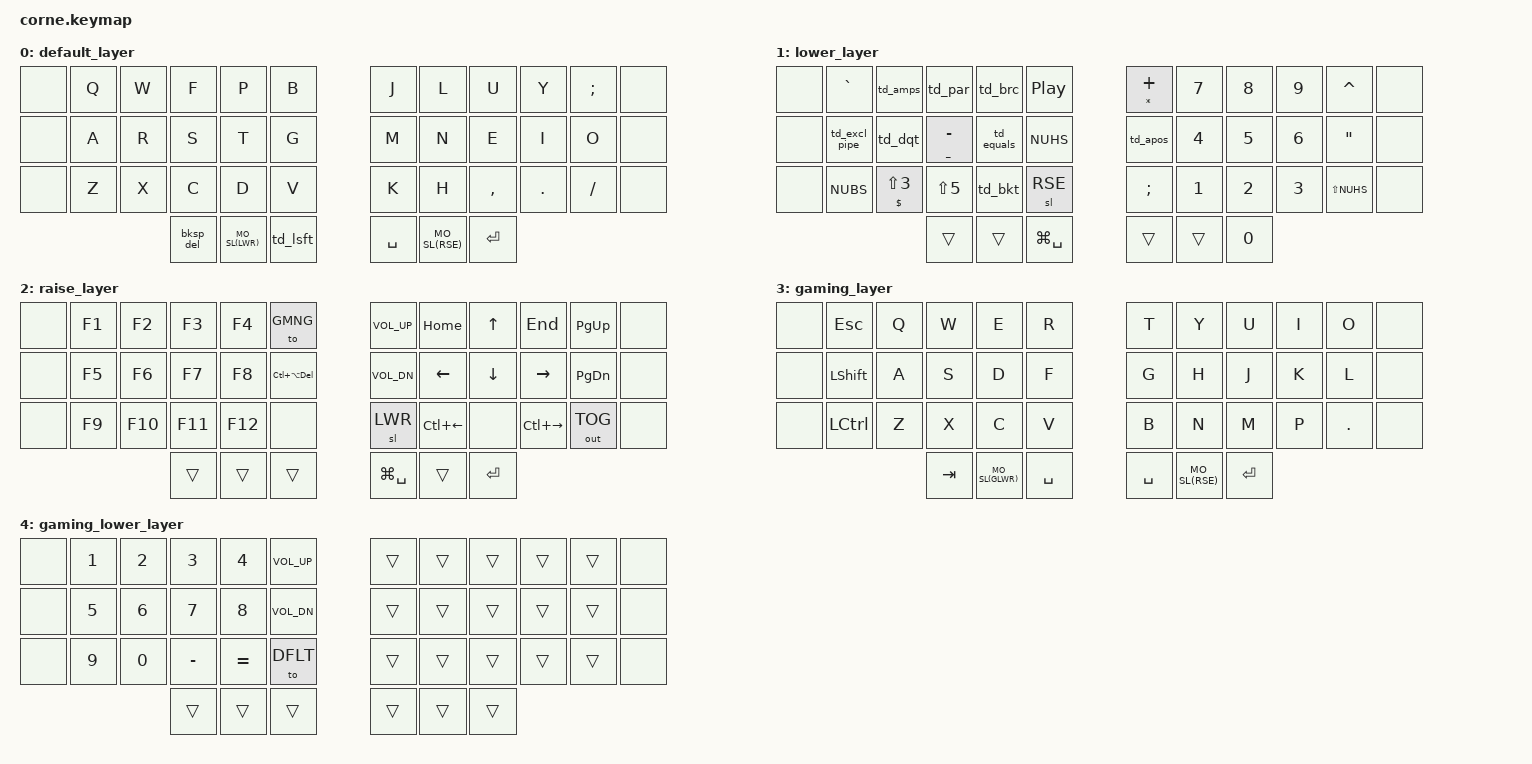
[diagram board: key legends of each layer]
/*
 * Copyright (c) 2020 The ZMK Contributors
 *
 * SPDX-License-Identifier: MIT
 */
 
/*__________________________          __________________________
XX| 1  | 2  | 3  | 4  | 5  |          | 6  | 7  | 8  | 9  | 10 |XX
XX| 13 | 14 | 15 | 16 | 17 |          | 18 | 19 | 20 | 21 | 22 |XX
XX| 25 | 26 | 27 | 28 | 29 |          | 30 | 31 | 32 | 33 | 34 |XX
                 | 36 | 37 | 38 || 39 | 40 | 41 | */

#include <behaviors.dtsi>
#include <dt-bindings/zmk/keys.h>
#include <dt-bindings/zmk/bt.h>
#include <dt-bindings/zmk/outputs.h>

#define MO_TOG(layer) &mo_tog layer layer // macro to apply momentary on hold, toggle on tap
#define MO_SL(layer) &mo_sl layer layer // macro to apply momentary on hold sticky on tap

#define DFLT 0
#define LWR 1
#define RSE 2
#define GMNG 3
#define GLWR 4

#define TD_TAPTERM 175
#define LAYER_TAPTERM 175
#define COMBO_TIMEOUT 35
#define COMBO_TIMEOUT_FAST 30

#define QUICKTAP_MS 125
#define QUICKTAP_TERM 175

#define XX &none
#define TRNS &trans

/ {
        // conditional_layers {
        //         compatible = "zmk,conditional-layers";
        //         tri_layer {
        //                 if-layers = <LWR RSE>;
        //                 then-layer = <MISC>;
        //         };
        // };
        
        macros {
                parens: parens {
                        label = "parens";
                        compatible = "zmk,behavior-macro";
                        #binding-cells = <0>;
                        bindings = <&macro_tap &kp LPAR &kp RPAR>;
                };
                braces: braces {
                        label = "braces";
                        compatible = "zmk,behavior-macro";
                        #binding-cells = <0>;
                        bindings = <&macro_tap &kp LBRC &kp RBRC>;
                };
                brackets: brackets {
                        label = "brackets";
                        compatible = "zmk,behavior-macro";
                        #binding-cells = <0>;
                        bindings = <&macro_tap &kp LBKT &kp RBKT>;
                };
                prog_brackets: prog_brackets {
                        label = "prog_brackets";
                        compatible = "zmk,behavior-macro";
                        #binding-cells = <0>;
                        bindings = <&macro_tap &kp LBKT &kp RBKT>;
                };
                quotations: quotations {
                        label = "quotations";
                        compatible = "zmk,behavior-macro";
                        #binding-cells = <0>;
                        bindings = <&macro_tap &kp AT &kp AT &kp LEFT>;
                };
                apostrophes: apostrophes {
                        label = "apostrophes";
                        compatible = "zmk,behavior-macro";
                        #binding-cells = <0>;
                        bindings = <&macro_tap &kp APOS &kp APOS &kp LEFT>;
                };
                or: or {
                        label = "or";
                        compatible = "zmk,behavior-macro";
                        #binding-cells = <0>;
                        bindings = <&macro_tap &kp LS(NUBS) &kp LS(NUBS)>;
                };
                and: and {
                        label = "and";
                        compatible = "zmk,behavior-macro";
                        #binding-cells = <0>;
                        bindings = <&macro_tap &kp LS(N7) &kp LS(N7)>;
                };
                equals: equals {
                        label = "equals";
                        compatible = "zmk,behavior-macro";
                        #binding-cells = <0>;
                        bindings = <&macro_tap &kp EQUAL &kp EQUAL>;
                };
        };

        behaviors {
                mo_tog: behavior_mo_tog {
                        compatible = "zmk,behavior-hold-tap";
                        label = "mo_tog";
                        #binding-cells = <2>;
                        flavor = "balanced";
                        tapping-term-ms = <LAYER_TAPTERM>;
                        bindings = <&mo>, <&tog>;
                };
                mo_sl: behavior_mo_sl {
                        compatible = "zmk,behavior-hold-tap";
                        label = "mo_sl";
                        #binding-cells = <2>;
                        flavor = "balanced";
                        tapping-term-ms = <LAYER_TAPTERM>;
                        bindings = <&mo>, <&sl>;
                };
                td_lwr: behavior_td_lwr {
                        compatible = "zmk,behavior-tap-dance";
                        label = "td_lwr";
                        #binding-cells = <0>;
                        tapping-term-ms = <LAYER_TAPTERM>;
                        bindings = <MO_SL(LWR)>, <&tog LWR>;
                };
                td_rse: behavior_td_rse {
                        compatible = "zmk,behavior-tap-dance";
                        label = "td_rse";
                        #binding-cells = <0>;
                        tapping-term-ms = <LAYER_TAPTERM>;
                        bindings = <MO_SL(RSE)>, <&tog RSE>;
                };
                bksp_del: bksp_del {
                        compatible = "zmk,behavior-mod-morph";
                        label = "bksp_del";
                        #binding-cells = <0>;
                        bindings = <&kp BACKSPACE>, <&kp DELETE>;
                        mods = <(MOD_LCTL|MOD_RCTL|MOD_LSFT|MOD_RSFT)>;
                };
                skq: sticky_key_quick_release {
                        compatible = "zmk,behavior-sticky-key";
                        label = "STICKY_KEY_QUICK_RELEASE";
                        #binding-cells = <1>;
                        bindings = <&kp>;
                        release-after-ms = <1000>;
                        quick-release;
                };
                td_lsft: behavior_td_lsft {
                        compatible = "zmk,behavior-tap-dance";
                        label = "td_lsft";
                        #binding-cells = <0>;
                        tapping-term-ms = <TD_TAPTERM>;
                        bindings = <&skq LSFT>, <&caps_word>;
                };
                td_par: behavior_td_par {
                        compatible = "zmk,behavior-tap-dance";
                        label = "td_par";
                        #binding-cells = <0>;
                        tapping-term-ms = <TD_TAPTERM>;
                        bindings = <&mt RPAR LPAR>, <&parens>;
                };
                td_brc: behavior_td_brc {
                        compatible = "zmk,behavior-tap-dance";
                        label = "td_brc";
                        #binding-cells = <0>;
                        tapping-term-ms = <TD_TAPTERM>;
                        bindings = <&mt RBRC LBRC>, <&braces>;
                };
                gqt: global_quick_tap {
                        compatible = "zmk,behavior-hold-tap";
                        label = "gqt";
                        #binding-cells = <2>;
                        flavor = "tap-preferred";
                        tapping-term-ms = <QUICKTAP_TERM>;
                        quick-tap-ms = <QUICKTAP_MS>;
                        global-quick-tap;
                        bindings = <&kp>, <&kp>;
                };
                td_bkt: behavior_td_bkt {
                        compatible = "zmk,behavior-tap-dance";
                        label = "td_bkt";
                        #binding-cells = <0>;
                        tapping-term-ms = <TD_TAPTERM>;
                        bindings = <&mt RBKT LBKT>, <&brackets>;
                };
                td_excl_pipe: behavior_td_excl_pipe {
                        compatible = "zmk,behavior-tap-dance";
                        label = "td_excl_pipe";
                        #binding-cells = <0>;
                        tapping-term-ms = <TD_TAPTERM>;
                        bindings = <&gqt LS(NUBS) EXCL>, <&or>;
                };
                td_amps: behavior_td_amps {
                        compatible = "zmk,behavior-tap-dance";
                        label = "td_amps";
                        #binding-cells = <0>;
                        tapping-term-ms = <TD_TAPTERM>;
                        bindings = <&kp LS(N7)>, <&and>;
                };
                td_dqt: behavior_td_dqt {
                        compatible = "zmk,behavior-tap-dance";
                        label = "td_dqt";
                        #binding-cells = <0>;
                        tapping-term-ms = <TD_TAPTERM>;
                        bindings = <&kp AT>, <&quotations>;
                };
                td_apos: behavior_td_apos {
                        compatible = "zmk,behavior-tap-dance";
                        label = "td_apos";
                        #binding-cells = <0>;
                        tapping-term-ms = <TD_TAPTERM>;
                        bindings = <&kp APOS>, <&apostrophes>;
                };
                td_equals: behavior_td_equals {
                        compatible = "zmk,behavior-tap-dance";
                        label = "td_equals";
                        #binding-cells = <0>;
                        tapping-term-ms = <TD_TAPTERM>;
                        bindings = <&kp EQUAL>, <&equals>;
                };
        };
        
        combos{
                compatible = "zmk,combos";
                // left side
                combo_tab {
                        timeout-ms = <COMBO_TIMEOUT_FAST>;
                        key-positions = <13 14>;
                        bindings = <&kp TAB>;
                        layers = <DFLT RSE>;
                };
                combo_ctab {
                        timeout-ms = <COMBO_TIMEOUT>;
                        key-positions = <13 14>;
                        bindings = <&kp LC(TAB)>;
                        layers = <LWR>;
                };
                combo_gresc {
                        timeout-ms = <COMBO_TIMEOUT>;
                        key-positions = <1 2>;
                        bindings = <&gresc>;
                        layers = <DFLT LWR RSE>;
                };
                combo_lctrl {
                        timeout-ms = <COMBO_TIMEOUT>;
                        key-positions = <25 26>;
                        bindings = <&sk LCTRL>;
                        layers = <DFLT LWR RSE>;
                };
                combo_lgui {
                        timeout-ms = <COMBO_TIMEOUT_FAST>;
                        key-positions = <26 27>;
                        bindings = <&sk LGUI>;
                        layers = <DFLT LWR RSE>;
                };
                combo_lalt {
                        timeout-ms = <COMBO_TIMEOUT>;
                        key-positions = <27 28>;
                        bindings = <&sk LALT>;
                        layers = <DFLT LWR RSE>;
                };
                combo_lenter {
                        timeout-ms = <COMBO_TIMEOUT_FAST>;
                        key-positions = <16 17>;
                        bindings = <&kp ENTER>;
                        layers = <DFLT LWR RSE>;
                };
                //right side
                combo_backspace {
                        timeout-ms = <COMBO_TIMEOUT_FAST>;
                        key-positions = <9 10>;
                        bindings = <&bksp_del>;
                        layers = <DFLT LWR RSE>;
                };
                combo_rctrl {
                        timeout-ms = <COMBO_TIMEOUT>;
                        key-positions = <33 34>;
                        bindings = <&sk RCTRL>;
                        layers = <DFLT LWR RSE>;
                };
                combo_rgui {
                        timeout-ms = <COMBO_TIMEOUT_FAST>;
                        key-positions = <32 33>;
                        bindings = <&sk RGUI>;
                        layers = <DFLT LWR RSE>;
                };
                combo_ralt {
                        timeout-ms = <COMBO_TIMEOUT>;
                        key-positions = <31 32>;
                        bindings = <&sk LALT>;
                        layers = <DFLT LWR RSE>;
                };
                combo_rtab {
                        timeout-ms = <COMBO_TIMEOUT>;
                        key-positions = <18 19>;
                        bindings = <&kp ENTER>;
                        layers = <DFLT RSE>;
                };
                combo_rctab {
                        timeout-ms = <COMBO_TIMEOUT_FAST>;
                        key-positions = <18 19>;
                        bindings = <&kp LC(TAB)>;
                        layers = <LWR>;
                };
        };

        keymap {
                compatible = "zmk,keymap";

                default_layer {
/*_______________________________            _______________________________
XX|  Q  |  W  |  F  |  P  |  B  |            |  J  |  L  |  U  |  Y  |  ;  |XX
XX|  A  |  R  |  S  |  T  |  G  |            |  M  |  N  |  E  |  I  |  O  |XX
XX|  Z  |  X  |  C  |  D  |  V  |            |  K  |  H  |  ,  |  .  |  /  |XX
                    | BSP | LWR | SHF || SPC | RSE | ENT | */
                        bindings = <
XX &kp Q  &kp W  &kp F  &kp P  &kp B /**/ &kp J  &kp L  &kp U     &kp Y   &kp SEMI  XX
XX &kp A  &kp R  &kp S  &kp T  &kp G /**/ &kp M  &kp N  &kp E     &kp I   &kp O     XX
XX &kp Z  &kp X  &kp C  &kp D  &kp V /**/ &kp K  &kp H  &kp COMMA &kp DOT &kp FSLH  XX
/*TH*/ &bksp_del MO_SL(LWR) &td_lsft /**/ &kp SPACE MO_SL(RSE) &kp ENTER /*TH*/
                        >;
                };


                lower_layer {
/*_______________________________            _______________________________
XX| ESC |  &  | ()  | {}  |PLAY |            | +*  |  7  |  8  |  9  |  ^  |XX
XX| !|  | ""  | -_  |  =  |  #  |            | ''  |  4  |  5  |  6  |  @  |XX
XX|  \  | £$  |  %  | []  | RSE |            |  ;  |  1  |  2  |  3  |  ~  |XX
                    |-BSP-|-LWR-|APPS ||-SPC-|-RSE-|  0  | */
                        bindings = <
XX &kp GRAVE     &td_amps        &td_par         &td_brc    &kp C_PP /**/ &mt STAR PLUS &kp N7  &kp N8  &kp N9  &kp CARET     XX
XX &td_excl_pipe &td_dqt         &mt UNDER MINUS &td_equals &kp NUHS /**/ &td_apos      &kp N4  &kp N5  &kp N6  &kp DQT       XX
XX &kp NUBS      &mt DLLR LS(N3) &kp LS(N5)      &td_bkt    &sl RSE  /**/ &kp SEMI      &kp N1  &kp N2  &kp N3  &kp LS(NUHS)  XX
                                        /*TH*/ TRNS TRNS &kp LG(SPC) /**/ TRNS TRNS &kp N0 /*TH*/
                        >;
                };


                raise_layer {
/*_______________________________             _______________________________
XX| F1  | F2  | F3  | F4  |GAME |             |VOL+ |HOME | UP  | END |PGUP |XX
XX| F5  | F6  | F7  | F8  |CAD  |             |VOL- |LEFT |DOWN |RIGHT|PGDN |XX
XX| F9  | F10 | F11 | F12 |     |             | LWR |WDLFT|     |WDRT |OUTPT|XX
                     |-BSP-|-LWR-|-SHF-||APPS |-RSE-|-ENT-| */
                        bindings = <
XX &kp F1 &kp F2  &kp F3  &kp F4  &to GMNG        /**/ &kp C_VOL_UP &kp HOME     &kp UP   &kp END       &kp PG_UP    XX
XX &kp F5 &kp F6  &kp F7  &kp F8  &kp LC(LA(DEL)) /**/ &kp C_VOL_DN &kp LEFT     &kp DOWN &kp RIGHT     &kp PG_DN    XX
XX &kp F9 &kp F10 &kp F11 &kp F12 &none           /**/ &sl LWR      &kp LC(LEFT) &none    &kp LC(RIGHT) &out OUT_TOG XX
                            /*TH*/ TRNS TRNS TRNS /**/ &kp LG(SPC) TRNS &kp RET /*TH*/
                        >;
                };

//                 misc_layer {
// /*_______________________________            _______________________________
// XX| PWR |     |     |     |     |            |BRT+ |     |     |     | LCK |XX
// XX| BT0 | BT1 | BT2 | BT3 | BT4 |            |BRT- |BTCL |     |     |     |XX
// XX|     |     |     |     |     |            |     |     |     |     |     |XX
//                     |-BSP-|-LWR-|-SHF-|| XX  | XX  | XX  | */
//                         bindings = <
// XX  &none        &none        &none        &none        &none         /**/  &kp C_BRI_UP &none  &none  &none  &none XX
// XX  &bt BT_SEL 0 &bt BT_SEL 1 &bt BT_SEL 2 &bt BT_SEL 3 &bt BT_SEL 4  /**/  &kp C_BRI_DN &none  &none  &none  &none XX
// XX  &bt BT_CLR   &none        &none        &none        &none         /**/  &none        &none  &none  &none  &none XX
//                                                   &none  &none  &none /**/ &none  &none  &none
//                         >;
//                 };

                gaming_layer {
/*_______________________________            _______________________________
XX| ESC |  Q  |  W  |  E  |  R  |            |  J  |  L  |  U  |  Y  |  ;  |XX
XX|SHIFT|  A  |  S  |  D  |  F  |            |  M  |  N  |  E  |  I  |  O  |XX
XX|CTRL |  Z  |  X  |  C  |  V  |            |  K  |  H  |  ,  |  .  |  /  |XX
                    | TAB |GLWR | SPC || SPC | RSE | ENT |*/
                        bindings = <
XX &kp ESC   &kp Q  &kp W  &kp E  &kp R /**/ &kp T  &kp Y  &kp U  &kp I  &kp O    XX 
XX &kp LSHFT &kp A  &kp S  &kp D  &kp F /**/ &kp G  &kp H  &kp J  &kp K  &kp L    XX
XX &kp LCTRL &kp Z  &kp X  &kp C  &kp V /**/ &kp B  &kp N  &kp M  &kp P  &kp DOT  XX
   /*TH*/ &kp TAB MO_SL(GLWR) &kp SPACE /**/ &kp SPACE MO_SL(RSE) &kp ENTER /*TH*/
                        >;
                };
                
                gaming_lower_layer {
/*_______________________________            _______________________________
XX|  1  |  2  |  3  |  4  |VOL+ |            |--J--|--L--|--U--|--Y--|--;--|XX
XX|  5  |  6  |  7  |  8  |VOL- |            |--M--|--N--|--E--|--I--|--O--|XX
XX|  9  |  0  |  -  |  =  |DFLT |            |--K--|--H--|--,--|--.--|--/--|XX
                    |-TAB-|-NUM-|-SPC-||-SPC-|-RSE-|-ENT-| */
                        bindings = <
XX &kp N1  &kp N2  &kp N3    &kp N4    &kp C_VOL_UP /**/ TRNS TRNS TRNS TRNS TRNS XX
XX &kp N5  &kp N6  &kp N7    &kp N8    &kp C_VOL_DN /**/ TRNS TRNS TRNS TRNS TRNS XX
XX &kp N9  &kp N0  &kp MINUS &kp EQUAL &to DFLT     /**/ TRNS TRNS TRNS TRNS TRNS XX
                              /*TH*/ TRNS TRNS TRNS /**/ TRNS TRNS TRNS /*TH*/
                        >;
                };

        };
};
